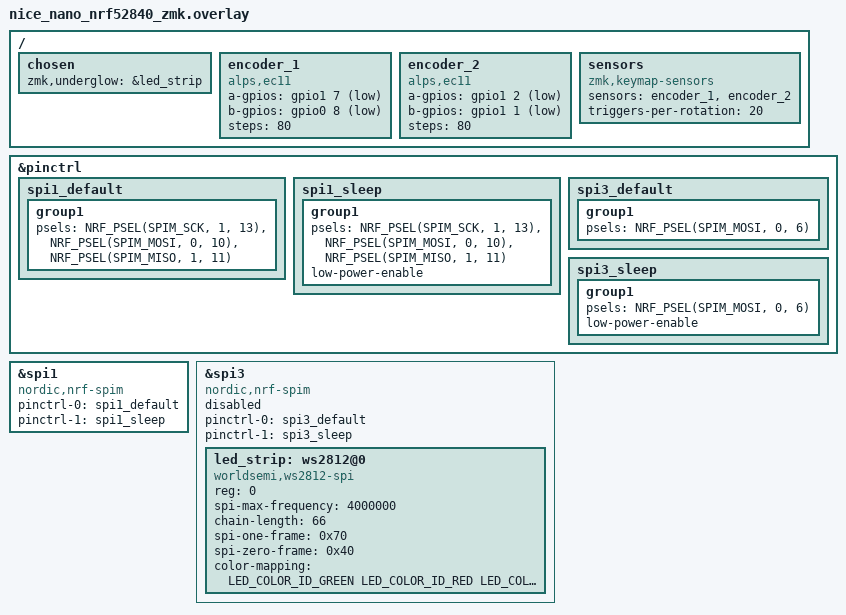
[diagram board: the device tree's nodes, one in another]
#include <dt-bindings/led/led.h>

&pinctrl {
    spi1_default: spi1_default {
        group1 {
            psels = <NRF_PSEL(SPIM_SCK, 1, 13)>,
                <NRF_PSEL(SPIM_MOSI, 0, 10)>,
                <NRF_PSEL(SPIM_MISO, 1, 11)>;
        };
    };

    spi1_sleep: spi1_sleep {
        group1 {
            psels = <NRF_PSEL(SPIM_SCK, 1, 13)>,
                <NRF_PSEL(SPIM_MOSI, 0, 10)>,
                <NRF_PSEL(SPIM_MISO, 1, 11)>;
            low-power-enable;
        };
    };

    spi3_default: spi3_default {
        group1 {
            psels = <NRF_PSEL(SPIM_MOSI, 0, 6)>;
        };
    };

    spi3_sleep: spi3_sleep {
        group1 {
            psels = <NRF_PSEL(SPIM_MOSI, 0, 6)>;
            low-power-enable;
        };
    };
};

&spi1 {
    compatible = "nordic,nrf-spim";
    pinctrl-0 = <&spi1_default>;
    pinctrl-1 = <&spi1_sleep>;
    pinctrl-names = "default", "sleep";
};

&spi3 {
    compatible = "nordic,nrf-spim";
    status = "disabled";

    pinctrl-0 = <&spi3_default>;
    pinctrl-1 = <&spi3_sleep>;
    pinctrl-names = "default", "sleep";

    led_strip: ws2812@0 {
        compatible = "worldsemi,ws2812-spi";

        /* SPI */
        reg = <0>; /* ignored, but necessary for SPI bindings */
        spi-max-frequency = <4000000>;

        /* WS2812 */
        chain-length = <66>; /* arbitrary; change at will */
        spi-one-frame = <0x70>;
        spi-zero-frame = <0x40>;

        color-mapping = <LED_COLOR_ID_GREEN LED_COLOR_ID_RED LED_COLOR_ID_BLUE>;
    };
};

/ {
    chosen {
        zmk,underglow = &led_strip;
    };

    // Left encoder
    encoder_1: encoder_1 {
        compatible = "alps,ec11";
        a-gpios = <&gpio1 7 (GPIO_ACTIVE_LOW | GPIO_PULL_UP)>;
        b-gpios = <&gpio0 8 (GPIO_ACTIVE_LOW | GPIO_PULL_UP)>;
        steps = <80>;
        status = "okay";
    };

    // Right encoder
    encoder_2: encoder_2 {
        compatible = "alps,ec11";
        a-gpios = <&gpio1 2 (GPIO_ACTIVE_LOW | GPIO_PULL_UP)>;
        b-gpios = <&gpio1 1 (GPIO_ACTIVE_LOW | GPIO_PULL_UP)>;
        steps = <80>;
        status = "okay";
    };
    
    sensors {
        compatible = "zmk,keymap-sensors";
        sensors = <&encoder_1 &encoder_2>;
        triggers-per-rotation = <20>;
    };
};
